# netx90_app register map
File version: 1.0
CPU: CM4 r0p1, little endian, MPU, FPU, 4 interrupt priority bits, 78 interrupts
Registers are 32-bit, read-write, reset 0x0 unless marked. A register's access mark holds for its fields unless they carry their own. Offsets are from the block's base; [hi:lo] are bit positions; 'fields as' and 'values as' point back to an identical list.

## xpic_app_debug
Base 0xFF884080
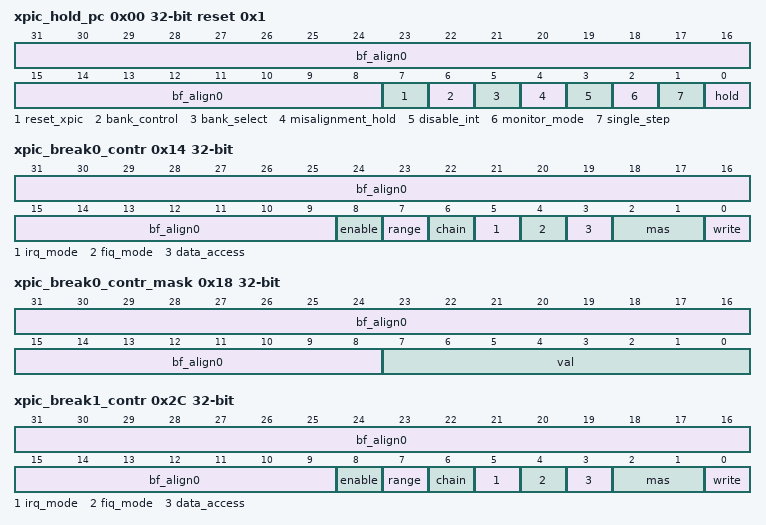
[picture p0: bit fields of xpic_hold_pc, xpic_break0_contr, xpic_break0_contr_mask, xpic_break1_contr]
0x00 xpic_hold_pc reset 0x1 (reset mask 0xFF) — no Register description
  [31:8] bf_align0 — bitField alignment value for aeabi compatibility
  [7] reset_xpic — REQUEST reset all internal internal states and the pipeline EXCEPT: the internal register (r0-r7, usr0-4), bank0 and bank1 reset this registers manually EXCEPT: xpic hard_breaker/debug registers 1 - xPIC reset request
  [6] bank_control — control over the register bank selection WARNING: reset this BIT to 0 BEFORE start xPIC (clear hold bits)
  [5] bank_select — Select register bank (0: default bank, 1: fiq bank) Access registers in xpic_regs area (xpic_r0 .. xpic_r7, xpic_stat)
  [4] misalignment_hold — 0: xPIC triggers misalignment_irq on misaligned memory accesses but does not stop. 1: xPIC stops after a misaligned memory accesses and triggers misalignment_irq. Write '1' into xpic_break_irq_raw.misalignment_irq to continue.
  [3] disable_int — disable interrupts
  [2] monitor_mode — 0: xPIC stops when hardware breakpoint is triggered. Write '1' into xpic_break_irq_raw.break0_irq or break1_irq to continue. 1: Hardware breakpoints still generate irqs but do not stop the xPIC.
  [1] single_step — 0: Disable single step mode 1: xPIC processes a single pipeline step then stops and triggers the single_step_irq. Write '1' into xpic_break_irq_raw.single_step_irq to continue.
  [0] hold — 0: Start xPIC 1: Hold xPIC
0x04 xpic_break0_addr — no Register description
  [31:0] val — Breakpoint 0 address value
0x08 xpic_break0_addr_mask — no Register description
  [31:0] val — Breakpoint 0 address mask
0x0C xpic_break0_data — no Register description
  [31:0] val — Breakpoint 0 data value (for data access only)
0x10 xpic_break0_data_mask — no Register description
  [31:0] val — Breakpoint 0 data mask (for data access only)
0x14 xpic_break0_contr (reset mask 0x1FF) — no Register description
  [31:9] bf_align0 — bitField alignment value for aeabi compatibility
  [8] enable — Breakpoint 0
  [7] range — Breakpoint 0 input from Breakpoint 1
  [6] chain — Breakpoint 0 input from Breakpoint 1
  [5] irq_mode — Breakpoint 0 xPIC in IRQ Mode
  [4] fiq_mode — Breakpoint 0 xPIC in FIQ Mode
  [3] data_access — Breakpoint 0 (1: data access, 0: instruction fetch)
  [2:1] mas — Breakpoint 0 memory access size (00: byte. 01: word, 10 dword, 11 reserved)
  [0] write — Breakpoint 0 write/read access
0x18 xpic_break0_contr_mask (reset mask 0xFF) — no Register description
  [31:8] bf_align0 — bitField alignment value for aeabi compatibility
  [7:0] val — Breakpoint 0 control mask
0x1C xpic_break1_addr — no Register description
  [31:0] val — Breakpoint 1 address value
0x20 xpic_break1_addr_mask — no Register description
  [31:0] val — Breakpoint 1 address mask
0x24 xpic_break1_data — no Register description
  [31:0] val — Breakpoint 1 data value (for data access only)
0x28 xpic_break1_data_mask — no Register description
  [31:0] val — Breakpoint 1 data mask (for data access only)
0x2C xpic_break1_contr (reset mask 0x1FF) — no Register description
  [31:9] bf_align0 — bitField alignment value for aeabi compatibility
  [8] enable — Breakpoint 1
  [7] range — reserved value
  [6] chain — reserved value
  [5] irq_mode — Breakpoint 1 xPIC in IRQ Mode
  [4] fiq_mode — Breakpoint 1 xPIC in FIQ Mode
  [3] data_access — Breakpoint 1 (1: data access, 0: instruction fetch)
  [2:1] mas — Breakpoint 1 memory access size (00: byte. 01: word, 10 dword, 11 reserved)
  [0] write — Breakpoint 1 write/read access
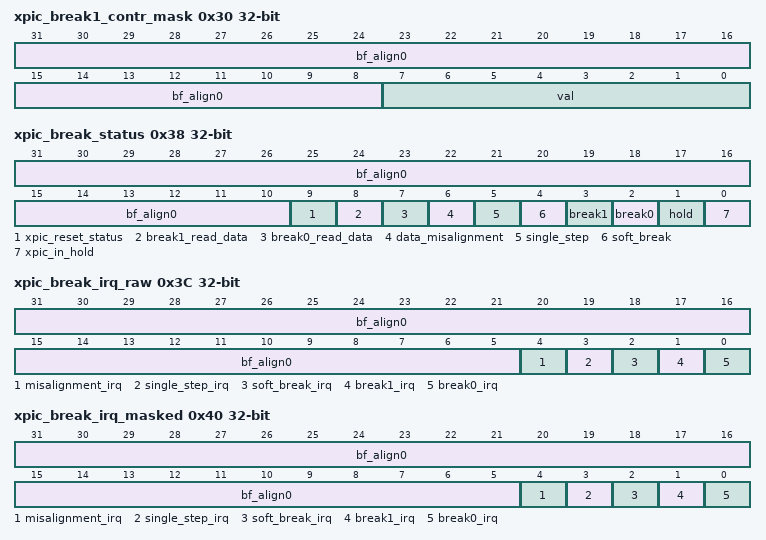
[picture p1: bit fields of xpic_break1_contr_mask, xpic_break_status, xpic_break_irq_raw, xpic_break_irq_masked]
0x30 xpic_break1_contr_mask (reset mask 0xFF) — no Register description
  [31:8] bf_align0 — bitField alignment value for aeabi compatibility
  [7:0] val — Breakpoint 1 control mask
0x34 xpic_break_last_pc ro — no Register description
  [31:0] val — last PC
0x38 xpic_break_status ro (reset mask 0x3FF) — Read access shows the reason why xPIC is in HOLD / BREAK
  [31:10] bf_align0 — bitField alignment value for aeabi compatibility
  [9] xpic_reset_status — 1 = XPIC ist in Reset(read only)
  [8] break1_read_data — Breakpoint 1 last load access (read only)
  [7] break0_read_data — Breakpoint 0 last load access (read only)
  [6] data_misalignment — Data Misaligment is active(read only)
  [5] single_step — Single Step Break is active(read only)
  [4] soft_break — Software Break is active(read only)
  [3] break1 — Breakpoint 1 is active(read only)
  [2] break0 — Breakpoint 0 is active(read only)
  [1] hold — global HOLD BIT status 0- start xPIC, 1- hold xPIC (read only)
  [0] xpic_in_hold — xPIC is in Break or Hold (read only)
0x3C xpic_break_irq_raw (reset mask 0x1F) — xPIC_DEBUG Raw IRQ register: Read access shows status of unmasked IRQs. IRQs are set automatically and reset by writing to this register: Write access with '1' resets the appropriate IRQ. Write access with '0' does not influence this bit.
  [31:5] bf_align0 — bitField alignment value for aeabi compatibility
  [4] misalignment_irq — Data Misalignment Error Interrupt
  [3] single_step_irq — single step Breakpoint Interrupt
  [2] soft_break_irq — Software Breakpoint Interrupt
  [1] break1_irq — Breakpoint 1 Interrupt
  [0] break0_irq — Breakpoint 0 Interrupt
0x40 xpic_break_irq_masked ro (reset mask 0x1F) — xPIC_DEBUG Masked IRQ register for other CPU (ARM): Shows status of masked IRQs (as connected to ARM)
  fields as xpic_break_irq_raw
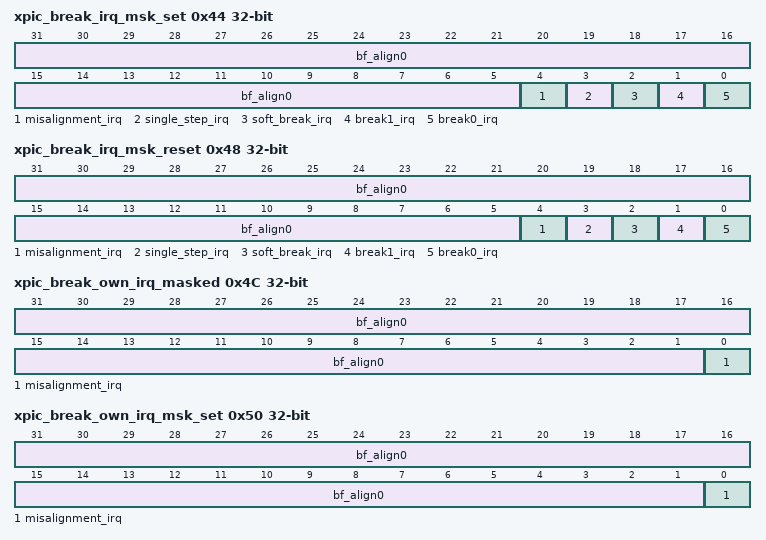
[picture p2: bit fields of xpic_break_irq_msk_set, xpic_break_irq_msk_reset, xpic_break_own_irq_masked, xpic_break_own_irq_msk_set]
0x44 xpic_break_irq_msk_set (reset mask 0x1F) — xPIC_DEBUG interrupt mask set for other CPU (ARM): The IRQ mask enables interrupt requests for corresponding interrupt sources. As its bits might be changed by different software tasks, the IRQ mask register is not writable directly, but by set and reset masks: Write access with '1' sets interrupt mask bit (enables interrupt request for corresponding interrupt source). Write access with '0' does not influence this bit. Read access shows actual interrupt mask. Attention: Before activating interrupt mask, delete old pending interrupts by writing the same value to xpic_break_irq_raw.
  fields as xpic_break_irq_raw
0x48 xpic_break_irq_msk_reset (reset mask 0x1F) — xPIC_DEBUG interrupt mask reset for other CPU (ARM): This is the corresponding reset mask to disable interrupt requests for corresponding interrupt sources: Write access with '1' resets interrupt mask bit (disables interrupt request for corresponding interrupt source). Write access with '0' does not influence this bit. Read access shows actual interrupt mask.
  fields as xpic_break_irq_raw
0x4C xpic_break_own_irq_masked ro (reset mask 0x1) — xPIC_DEBUG own Masked IRQ register (for xPIC): Shows status of masked IRQs (as connected to xPIC)
  [31:1] bf_align0 — bitField alignment value for aeabi compatibility
  [0] misalignment_irq — Data Misalignment Error Interrupt
0x50 xpic_break_own_irq_msk_set (reset mask 0x1) — xPIC_DEBUG own interrupt mask set (for xPIC): The IRQ mask enables interrupt requests for corresponding interrupt sources. As its bits might be changed by different software tasks, the IRQ mask register is not writable directly, but by set and reset masks: Write access with '1' sets interrupt mask bit (enables interrupt request for corresponding interrupt source). Write access with '0' does not influence this bit. Read access shows actual interrupt mask. Attention: Before activating interrupt mask, delete old pending interrupts by writing the same value to xpic_break_irq_raw.
  fields as xpic_break_own_irq_masked
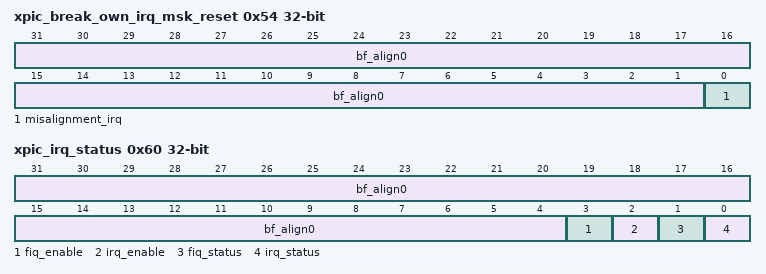
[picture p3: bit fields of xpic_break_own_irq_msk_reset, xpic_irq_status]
0x54 xpic_break_own_irq_msk_reset (reset mask 0x1) — xPIC_DEBUG own interrupt mask reset (for XPIC): This is the corresponding reset mask to disable interrupt requests for corresponding interrupt sources: Write access with '1' resets interrupt mask bit (disables interrupt request for corresponding interrupt source). Write access with '0' does not influence this bit. Read access shows actual interrupt mask.
  fields as xpic_break_own_irq_masked
0x58 xpic_break_return_fiq_pc ro — xPIC_DEBUG information FIQ return PC value valid if xPIC is in FIQ
  [31:0] val — xPIC FIQ return value
0x5C xpic_break_return_irq_pc ro — xPIC_DEBUG information last IRQ return PC value valid if xPIC is in IRQ
  [31:0] val — xPIC last IRQ return value
0x60 xpic_irq_status ro (reset mask 0xF) — Read access shows the xpic irq status and the xpic irq enable bits
  [31:4] bf_align0 — bitField alignment value for aeabi compatibility
  [3] fiq_enable — FIQ enable bit
  [2] irq_enable — IRQ enable bit
  [1] fiq_status
  [0] irq_status
